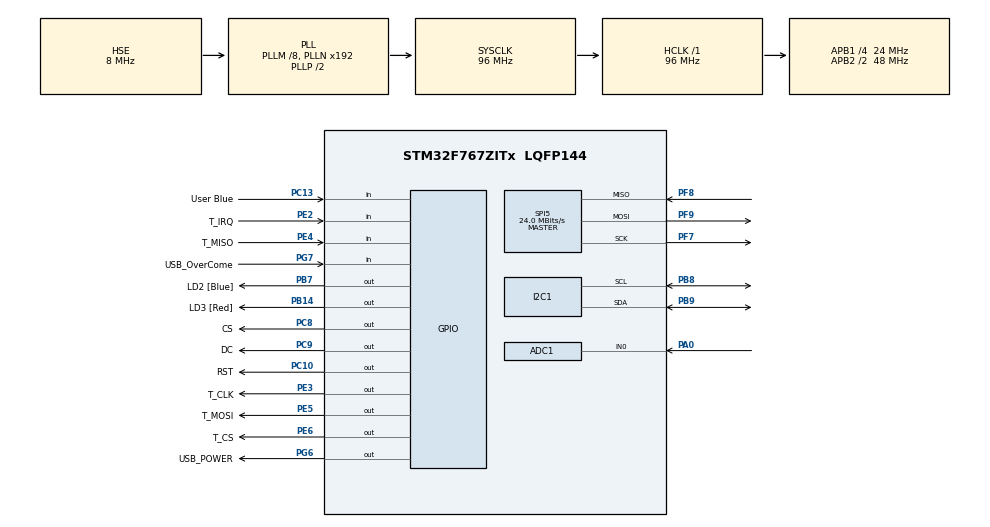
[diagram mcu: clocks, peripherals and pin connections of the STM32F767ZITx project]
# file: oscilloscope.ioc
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ADC1.Channel-0\#ChannelRegularConversion=ADC_CHANNEL_0
ADC1.ClockPrescaler=ADC_CLOCK_SYNC_PCLK_DIV4
ADC1.ContinuousConvMode=ENABLE
ADC1.DMAContinuousRequests=ENABLE
ADC1.EOCSelection=ADC_EOC_SINGLE_CONV
ADC1.NbrOfConversionFlag=1
ADC1.Rank-0\#ChannelRegularConversion=1
ADC1.SamplingTime-0\#ChannelRegularConversion=ADC_SAMPLETIME_3CYCLES
ADC1.master=1
CORTEX_M7.ART_ACCELERATOR_ENABLE=1
CORTEX_M7.CPU_DCache=Enabled
CORTEX_M7.CPU_ICache=Enabled
CORTEX_M7.MPU_Control=__NULL
CORTEX_M7.PREFETCH_ENABLE=1
CORTEX_M7.default_mode_Activation=1
Dma.ADC1.0.Direction=DMA_PERIPH_TO_MEMORY
Dma.ADC1.0.FIFOMode=DMA_FIFOMODE_DISABLE
Dma.ADC1.0.Instance=DMA2_Stream0
Dma.ADC1.0.MemDataAlignment=DMA_MDATAALIGN_HALFWORD
Dma.ADC1.0.MemInc=DMA_MINC_ENABLE
Dma.ADC1.0.Mode=DMA_NORMAL
Dma.ADC1.0.PeriphDataAlignment=DMA_PDATAALIGN_HALFWORD
Dma.ADC1.0.PeriphInc=DMA_PINC_DISABLE
Dma.ADC1.0.Priority=DMA_PRIORITY_HIGH
Dma.Request0=ADC1
I2C1.Timing=0x00506682
Mcu.Family=STM32F7
Mcu.Name=STM32F767ZITx
Mcu.Package=LQFP144
NVIC.ADC_IRQn=true\:5\:0\:false\:false\:true\:true\:true\:true
NVIC.DMA2_Stream0_IRQn=true\:5\:0\:false\:false\:true\:false\:true\:true
NVIC.PriorityGroup=NVIC_PRIORITYGROUP_4
PA0/WKUP.Signal=ADCx_IN0
PB14.GPIO_Label=LD3 [Red]
PB14.Signal=GPIO_Output
PB7.GPIO_Label=LD2 [Blue]
PB7.Signal=GPIO_Output
PB8.GPIO_Pu=GPIO_PULLUP
PB8.Mode=I2C
PB8.Signal=I2C1_SCL
PB9.GPIO_Pu=GPIO_PULLUP
PB9.Mode=I2C
PB9.Signal=I2C1_SDA
PC10.GPIO_Label=RST
PC10.GPIO_Speed=GPIO_SPEED_FREQ_VERY_HIGH
PC10.Signal=GPIO_Output
PC13.GPIO_Label=User Blue
PC13.Signal=GPIO_Input
PC8.GPIO_Label=CS
PC8.GPIO_Speed=GPIO_SPEED_FREQ_VERY_HIGH
PC8.Signal=GPIO_Output
PC9.GPIO_Label=DC
PC9.GPIO_Speed=GPIO_SPEED_FREQ_VERY_HIGH
PC9.Signal=GPIO_Output
PE2.GPIO_Label=T_IRQ
PE2.Signal=GPIO_Input
PE3.GPIO_Label=T_CLK
PE3.GPIO_Speed=GPIO_SPEED_FREQ_VERY_HIGH
PE3.Signal=GPIO_Output
PE4.GPIO_Label=T_MISO
PE4.Signal=GPIO_Input
PE5.GPIO_Label=T_MOSI
PE5.GPIO_Speed=GPIO_SPEED_FREQ_VERY_HIGH
PE5.Signal=GPIO_Output
PE6.GPIO_Label=T_CS
PE6.GPIO_Speed=GPIO_SPEED_FREQ_VERY_HIGH
PE6.Signal=GPIO_Output
PF7.Mode=Full_Duplex_Master
PF7.Signal=SPI5_SCK
PF8.Mode=Full_Duplex_Master
PF8.Signal=SPI5_MISO
PF9.Mode=Full_Duplex_Master
PF9.Signal=SPI5_MOSI
PG6.GPIO_Label=USB_POWER
PG6.Signal=GPIO_Output
PG7.GPIO_Label=USB_OverCome
PG7.Signal=GPIO_Input
PH0/OSC_IN.Mode=HSE-External-Oscillator
PH0/OSC_IN.Signal=RCC_OSC_IN
PH1/OSC_OUT.Mode=HSE-External-Oscillator
PH1/OSC_OUT.Signal=RCC_OSC_OUT
ProjectManager.HeapSize=0x200
ProjectManager.StackSize=0x400
ProjectManager.TargetToolchain=STM32CubeIDE
RCC.AHBFreq_Value=96000000
RCC.APB1CLKDivider=RCC_HCLK_DIV4
RCC.APB1Freq_Value=24000000
RCC.APB1TimFreq_Value=48000000
RCC.APB2CLKDivider=RCC_HCLK_DIV2
RCC.APB2Freq_Value=48000000
RCC.APB2TimFreq_Value=96000000
RCC.CortexFreq_Value=96000000
RCC.HCLKFreq_Value=96000000
RCC.HSE_VALUE=8000000
RCC.HSI_VALUE=16000000
RCC.LSE_VALUE=32768
RCC.PLLM=8
RCC.PLLQ=9
RCC.PLLSourceVirtual=RCC_PLLSOURCE_HSE
RCC.SYSCLKFreq_VALUE=96000000
RCC.SYSCLKSource=RCC_SYSCLKSOURCE_PLLCLK
RCC.USBFreq_Value=21333333.333333332
RCC.VCOOutputFreq_Value=192000000
SH.ADCx_IN0.0=ADC1_IN0,IN0
SPI5.BaudRatePrescaler=SPI_BAUDRATEPRESCALER_2
SPI5.CalculateBaudRate=24.0 MBits/s
SPI5.DataSize=SPI_DATASIZE_8BIT
SPI5.Direction=SPI_DIRECTION_2LINES
SPI5.Mode=SPI_MODE_MASTER
SPI5.NSSPMode=SPI_NSS_PULSE_DISABLE
SPI5.VirtualType=VM_MASTER
TIM1.ClockDivision=TIM_CLOCKDIVISION_DIV2
TIM1.Period=0
TIM1.Prescaler=10000
VP_RNG_VS_RNG.Mode=RNG_Activate
VP_TIM1_VS_ClockSourceINT.Mode=Internal
board=custom

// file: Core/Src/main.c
/* USER CODE BEGIN Header */
/**
  ******************************************************************************
  * @file           : main.c
  * @brief          : Main program body
  ******************************************************************************
  * @attention
  *
  * Copyright (c) 2026 STMicroelectronics.
  * All rights reserved.
  *
  * This software is licensed under terms that can be found in the LICENSE file
  * in the root directory of this software component.
  * If no LICENSE file comes with this software, it is provided AS-IS.
  *
  ******************************************************************************
  */
/* USER CODE END Header */
#include "main.h"
#include "adc.h"
#include "dma.h"
#include "i2c.h"
#include "rng.h"
#include "spi.h"
#include "tim.h"
#include "gpio.h"

/* USER CODE BEGIN Includes */
#include "app/app.h"
/* USER CODE END Includes */

void SystemClock_Config(void);

int main(void)
{

  /* Enable the CPU Cache */

  /* Enable I-Cache---------------------------------------------------------*/
  SCB_EnableICache();

  /* Enable D-Cache---------------------------------------------------------*/
  SCB_EnableDCache();

  /* MCU Configuration--------------------------------------------------------*/

  /* Reset of all peripherals, Initializes the Flash interface and the Systick. */
  HAL_Init();

  /* Configure the system clock */
  SystemClock_Config();

  /* Initialize all configured peripherals */
  MX_GPIO_Init();
  MX_DMA_Init();
  MX_RNG_Init();
  MX_SPI5_Init();
  MX_TIM1_Init();
  MX_I2C1_Init();
  MX_ADC1_Init();
  /* USER CODE BEGIN 2 */
  AppInit();
  AppStart();
  /* USER CODE END 2 */

  /* Infinite loop */
  while (1)
  {

  }
}

void SystemClock_Config(void)
{
  RCC_OscInitTypeDef RCC_OscInitStruct = {0};
  RCC_ClkInitTypeDef RCC_ClkInitStruct = {0};

  /** Configure the main internal regulator output voltage
  */
  __HAL_RCC_PWR_CLK_ENABLE();
  __HAL_PWR_VOLTAGESCALING_CONFIG(PWR_REGULATOR_VOLTAGE_SCALE3);

  /** Initializes the RCC Oscillators according to the specified parameters
  * in the RCC_OscInitTypeDef structure.
  */
  RCC_OscInitStruct.OscillatorType = RCC_OSCILLATORTYPE_HSE;
  RCC_OscInitStruct.HSEState = RCC_HSE_ON;
  RCC_OscInitStruct.PLL.PLLState = RCC_PLL_ON;
  RCC_OscInitStruct.PLL.PLLSource = RCC_PLLSOURCE_HSE;
  RCC_OscInitStruct.PLL.PLLM = 8;
  RCC_OscInitStruct.PLL.PLLN = 192;
  RCC_OscInitStruct.PLL.PLLP = RCC_PLLP_DIV2;
  RCC_OscInitStruct.PLL.PLLQ = 9;
  RCC_OscInitStruct.PLL.PLLR = 2;
  if (HAL_RCC_OscConfig(&RCC_OscInitStruct) != HAL_OK)
  {
    Error_Handler();
  }

  /** Initializes the CPU, AHB and APB buses clocks
  */
  RCC_ClkInitStruct.ClockType = RCC_CLOCKTYPE_HCLK|RCC_CLOCKTYPE_SYSCLK
                              |RCC_CLOCKTYPE_PCLK1|RCC_CLOCKTYPE_PCLK2;
  RCC_ClkInitStruct.SYSCLKSource = RCC_SYSCLKSOURCE_PLLCLK;
  RCC_ClkInitStruct.AHBCLKDivider = RCC_SYSCLK_DIV1;
  RCC_ClkInitStruct.APB1CLKDivider = RCC_HCLK_DIV4;
  RCC_ClkInitStruct.APB2CLKDivider = RCC_HCLK_DIV2;

  if (HAL_RCC_ClockConfig(&RCC_ClkInitStruct, FLASH_LATENCY_3) != HAL_OK)
  {
    Error_Handler();
  }
}

void Error_Handler(void)
{
    __disable_irq();
    while (1) {}
}
#ifdef USE_FULL_ASSERT
/**
  * @brief  Reports the name of the source file and the source line number
  *         where the assert_param error has occurred.
  * @param  file: pointer to the source file name
  * @param  line: assert_param error line source number
  * @retval None
  */
void assert_failed(uint8_t *file, uint32_t line)
{
  /* USER CODE BEGIN 6 */
    (void)file; (void)line;
  /* USER CODE END 6 */
}
#endif /* USE_FULL_ASSERT */
